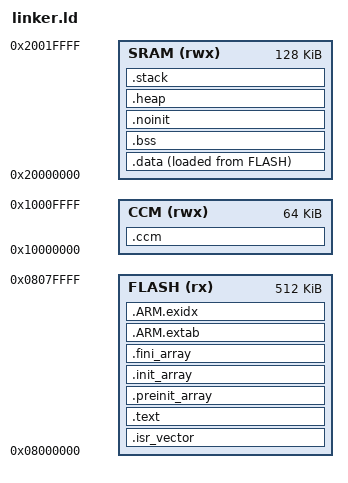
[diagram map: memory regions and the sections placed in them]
/* STM32F4 Linker Script for library tests */

ENTRY(_start)

MEMORY
{
    FLASH (rx)  : ORIGIN = 0x08000000, LENGTH = 512K
    SRAM (rwx)  : ORIGIN = 0x20000000, LENGTH = 128K
    CCM (rwx)   : ORIGIN = 0x10000000, LENGTH = 64K   /* Core Coupled Memory - fast */
}

_stack_size = 8K;
_heap_size = 32K;

SECTIONS
{
    .isr_vector :
    {
        . = ALIGN(4);
        KEEP(*(.isr_vector))
        . = ALIGN(4);
    } > FLASH

    .text :
    {
        . = ALIGN(4);
        *(.text)
        *(.text*)
        *(.rodata)
        *(.rodata*)
        . = ALIGN(4);
        _etext = .;
    } > FLASH

    .preinit_array :
    {
        . = ALIGN(4);
        __preinit_array_start = .;
        KEEP(*(.preinit_array*))
        __preinit_array_end = .;
    } > FLASH

    .init_array :
    {
        . = ALIGN(4);
        __init_array_start = .;
        KEEP(*(SORT(.init_array.*)))
        KEEP(*(.init_array*))
        __init_array_end = .;
    } > FLASH

    .fini_array :
    {
        . = ALIGN(4);
        __fini_array_start = .;
        KEEP(*(SORT(.fini_array.*)))
        KEEP(*(.fini_array*))
        __fini_array_end = .;
    } > FLASH

    .ARM.extab :
    {
        *(.ARM.extab* .gnu.linkonce.armextab.*)
    } > FLASH

    .ARM.exidx :
    {
        __exidx_start = .;
        *(.ARM.exidx* .gnu.linkonce.armexidx.*)
        __exidx_end = .;
    } > FLASH

    _sidata = LOADADDR(.data);

    .data :
    {
        . = ALIGN(4);
        _sdata = .;
        *(.data)
        *(.data*)
        . = ALIGN(4);
        _edata = .;
    } > SRAM AT> FLASH

    .bss :
    {
        . = ALIGN(4);
        _sbss = .;
        __bss_start__ = _sbss;
        *(.bss)
        *(.bss*)
        *(COMMON)
        . = ALIGN(4);
        _ebss = .;
        __bss_end__ = _ebss;
    } > SRAM

    .noinit (NOLOAD) :
    {
        . = ALIGN(4);
        *(.noinit)
        *(.noinit*)
        . = ALIGN(4);
    } > SRAM

    _end = .;

    .heap :
    {
        . = ALIGN(8);
        _heap_start = .;
        . = . + _heap_size;
        _heap_end = .;
    } > SRAM

    .stack :
    {
        . = ALIGN(8);
        _stack_end = .;
        . = . + _stack_size;
        _stack_start = .;
        _estack = .;
    } > SRAM

    .ccm (NOLOAD) :
    {
        . = ALIGN(4);
        *(.ccm)
        *(.ccm*)
    } > CCM
}

PROVIDE(_stack_top = _estack);
PROVIDE(_data_start = _sdata);
PROVIDE(_data_end = _edata);
PROVIDE(_data_loadaddr = _sidata);
PROVIDE(_bss_start = _sbss);
PROVIDE(_bss_end = _ebss);
